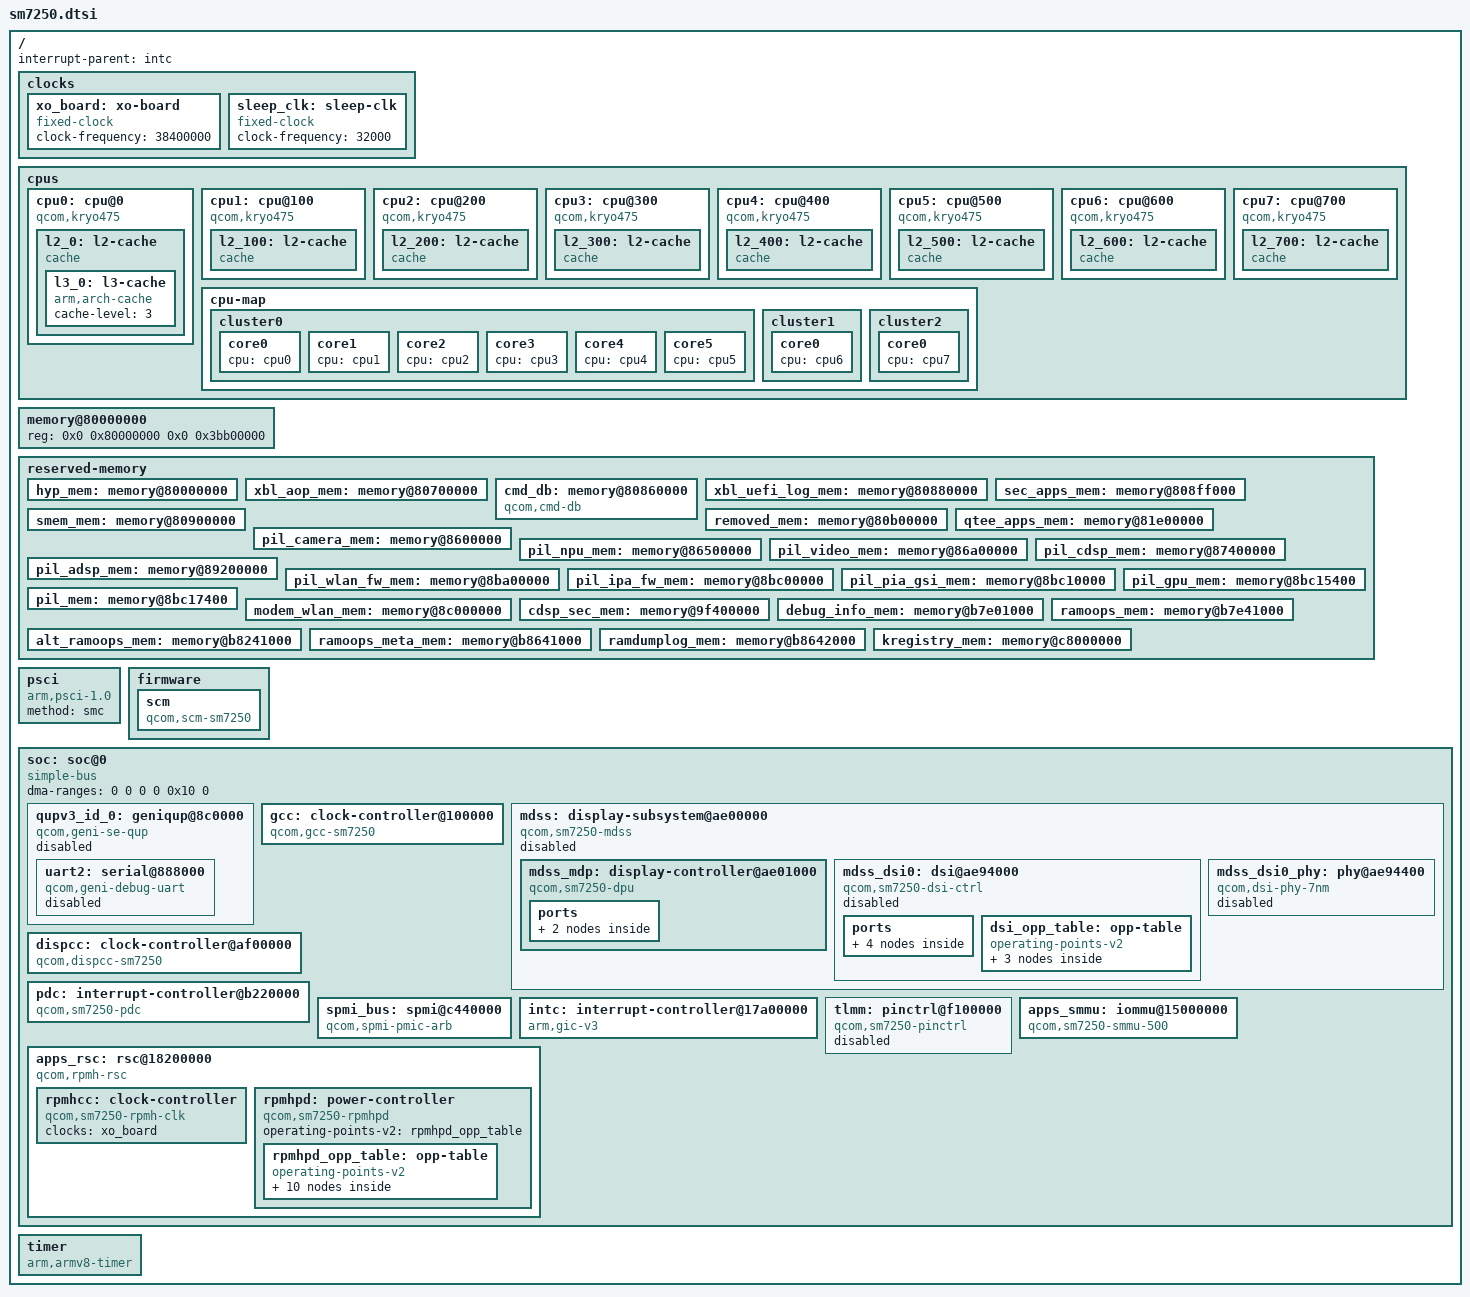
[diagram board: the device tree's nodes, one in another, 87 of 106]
// SPDX-License-Identifier: GPL-2.0
/*
 * Copyright (c) 2025 Mike Jones <mike@mjones.org>
 */

#include <dt-bindings/clock/qcom,dispcc-sm7250.h>
#include <dt-bindings/clock/qcom,dsi-phy-28nm.h>
#include <dt-bindings/clock/qcom,gcc-sm7250.h>
#include <dt-bindings/clock/qcom,rpmh.h>
#include <dt-bindings/interrupt-controller/arm-gic.h>
#include <dt-bindings/power/qcom,rpmhpd.h>
#include <dt-bindings/soc/qcom,rpmh-rsc.h>

/ {
	interrupt-parent = <&intc>;

	#address-cells = <2>;
	#size-cells = <2>;

	clocks {
		xo_board: xo-board {
			compatible = "fixed-clock";
			#clock-cells = <0>;
			clock-frequency = <38400000>;
		};

		sleep_clk: sleep-clk {
			compatible = "fixed-clock";
			#clock-cells = <0>;
			clock-frequency = <32000>;
		};
	};

	cpus {
		#address-cells = <0x02>;
		#size-cells = <0x00>;

		cpu0: cpu@0 {
			device_type = "cpu";
			compatible = "qcom,kryo475";
			reg = <0x0 0x0>;
			enable-method = "psci";
			capacity-dmips-mhz = <1024>;
			dynamic-power-coefficient = <100>;
			next-level-cache = <&l2_0>;
			#cooling-cells = <02>;

			l2_0: l2-cache {
				compatible = "cache";
				cache-level = <2>;
				next-level-cache = <&l3_0>;

				l3_0: l3-cache {
					compatible = "arm,arch-cache";
					cache-level = <3>;
				};
			};
		};
		cpu1: cpu@100 {
			device_type = "cpu";
			compatible = "qcom,kryo475";
			reg = <0x0 0x100>;
			enable-method = "psci";
			capacity-dmips-mhz = <1024>;
			dynamic-power-coefficient = <100>;
			next-level-cache = <&l2_100>;
			#cooling-cells = <02>;

			l2_100: l2-cache {
				compatible = "cache";
				cache-level = <2>;
				next-level-cache = <&l3_0>;
			};
		};

		cpu2: cpu@200 {
			device_type = "cpu";
			compatible = "qcom,kryo475";
			reg = <0x0 0x200>;
			enable-method = "psci";
			capacity-dmips-mhz = <1024>;
			dynamic-power-coefficient = <100>;
			next-level-cache = <&l2_200>;
			#cooling-cells = <02>;

			l2_200: l2-cache {
				compatible = "cache";
				cache-level = <2>;
				next-level-cache = <&l3_0>;
			};
		};
		cpu3: cpu@300 {
			device_type = "cpu";
			compatible = "qcom,kryo475";
			reg = <0x0 0x300>;
			enable-method = "psci";
			capacity-dmips-mhz = <1024>;
			dynamic-power-coefficient = <100>;
			next-level-cache = <&l2_300>;
			#cooling-cells = <02>;

			l2_300: l2-cache {
				compatible = "cache";
				cache-level = <2>;
				next-level-cache = <&l3_0>;
			};
		};

		cpu4: cpu@400 {
			device_type = "cpu";
			compatible = "qcom,kryo475";
			reg = <0x0 0x400>;
			enable-method = "psci";
			capacity-dmips-mhz = <1024>;
			dynamic-power-coefficient = <100>;
			next-level-cache = <&l2_400>;
			#cooling-cells = <02>;

			l2_400: l2-cache {
				compatible = "cache";
				cache-level = <2>;
				next-level-cache = <&l3_0>;
			};
		};

		cpu5: cpu@500 {
			device_type = "cpu";
			compatible = "qcom,kryo475";
			reg = <0x0 0x500>;
			enable-method = "psci";
			capacity-dmips-mhz = <1024>;
			dynamic-power-coefficient = <100>;
			next-level-cache = <&l2_500>;
			#cooling-cells = <02>;

			l2_500: l2-cache {
				compatible = "cache";
				cache-level = <2>;
				next-level-cache = <&l3_0>;
			};
		};

		cpu6: cpu@600 {
			device_type = "cpu";
			compatible = "qcom,kryo475";
			reg = <0x0 0x600>;
			enable-method = "psci";
			capacity-dmips-mhz = <1740>;
			dynamic-power-coefficient = <341>;
			next-level-cache = <&l2_600>;
			#cooling-cells = <2>;

			l2_600: l2-cache {
				compatible = "cache";
				cache-level = <2>;
				next-level-cache = <&l3_0>;
			};
		};

		cpu7: cpu@700 {
			device_type = "cpu";
			compatible = "qcom,kryo475";
			reg = <0x0 0x700>;
			enable-method = "psci";
			capacity-dmips-mhz = <1740>;
			dynamic-power-coefficient = <375>;
			next-level-cache = <&l2_700>;
			#cooling-cells = <2>;

			l2_700: l2-cache {
				compatible = "cache";
				cache-level = <2>;
				next-level-cache = <&l3_0>;
			};
		};

		cpu-map {

			cluster0 {

				core0 {
					cpu = <&cpu0>;
				};

				core1 {
					cpu = <&cpu1>;
				};

				core2 {
					cpu = <&cpu2>;
				};

				core3 {
					cpu = <&cpu3>;
				};

				core4 {
					cpu = <&cpu4>;
				};

				core5 {
					cpu = <&cpu5>;
				};
			};

			cluster1 {

				core0 {
					cpu = <&cpu6>;
				};
			};

			cluster2 {

				core0 {
					cpu = <&cpu7>;
				};
			};
		};
	};

	memory@80000000 {
		device_type = "memory";
		reg = <0x0 0x80000000 0x0 0x3bb00000>;
	};

	reserved-memory {
		#address-cells = <2>;
		#size-cells = <2>;
		ranges;

		hyp_mem: memory@80000000 {
			reg = <0x0 0x80000000 0x0 0x600000>;
			no-map;
		};

		xbl_aop_mem: memory@80700000 {
			reg = <0x0 0x80700000 0x0 0x160000>;
			no-map;
		};

		cmd_db: memory@80860000 {
			compatible = "qcom,cmd-db";
			reg = <0x0 0x80860000 0x0 0x20000>;
			no-map;
		};

		xbl_uefi_log_mem: memory@80880000 {
			reg = <0x0 0x80880000 0x0 0x14000>;
			no-map;
		};

		sec_apps_mem: memory@808ff000 {
			reg = <0x0 0x808ff000 0x0 0x1000>;
			no-map;
		};

		smem_mem: memory@80900000 {
			reg = <0x0 0x80900000 0x0 0x200000>;
			no-map;
		};

		removed_mem: memory@80b00000 {
			reg = <0x0 0x80b00000 0x0 0x1300000>;
			no-map;
		};

		qtee_apps_mem: memory@81e00000 {
			reg = <0x0 0x81e00000 0x0 0x2600000>;
			no-map;
		};

		pil_camera_mem: memory@8600000 {
			reg = <0x0 0x86000000 0x0 0x500000>;
			no-map;
		};

		pil_npu_mem: memory@86500000 {
			reg = <0x0 0x86500000 0x0 0x500000>;
			no-map;
		};

		pil_video_mem: memory@86a00000 {
			reg = <0x0 0x86a00000 0x0 0x500000>;
			no-map;
		};

		pil_cdsp_mem: memory@87400000 {
			reg = <0x0 0x87400000 0x0 0x1e00000>;
			no-map;
		};

		pil_adsp_mem: memory@89200000 {
			reg = <0x0 0x89200000 0x0 0x2800000>;
			no-map;
		};

		pil_wlan_fw_mem: memory@8ba00000 {
			reg = <0x0 0x8ba00000 0x0 0x200000>;
			no-map;
		};

		pil_ipa_fw_mem: memory@8bc00000 {
			reg = <0x0 0x8bc00000 0x0 0x10000>;
			no-map;
		};

		pil_pia_gsi_mem: memory@8bc10000 {
			reg = <0x0 0x8bc10000 0x0 0x5400>;
			no-map;
		};

		pil_gpu_mem: memory@8bc15400 {
			reg = <0x0 0x8bc15400 0x0 0x2000>;
			no-map;
		};

		pil_mem: memory@8bc17400 {
			reg = <0x0 0x8bc17400 0x0 0x3e8c00>;
			no-map;
		};

		modem_wlan_mem: memory@8c000000 {
			reg = <0x0 0x8c000000 0x0 0x11800000>;
			no-map;
		};

		cdsp_sec_mem: memory@9f400000 {
			reg = <0x0 0x9f400000 0x0 0xc00000>;
			no-map;
		};

		debug_info_mem: memory@b7e01000 {
			reg = <0x0 0xb7e01000 0x0 0x40000>;
			no-map;
		};

		ramoops_mem: memory@b7e41000 {
			reg = <0x0 0xb7e41000 0x0 0x400000>;
			no-map;
		};

		alt_ramoops_mem: memory@b8241000 {
			reg = <0x00 0xb8241000 0x00 0x400000>;
			no-map;
		};

		ramoops_meta_mem: memory@b8641000 {
			reg = <0x0 0xb8641000 0x0 0x1000>;
			no-map;
		};

		ramdumplog_mem: memory@b8642000 {
			reg = <0x0 0xb8642000 0x0 0x10000>;
			no-map;
		};

		kregistry_mem: memory@c8000000 {
			reg = <0x0 0xc8000000 0x0 0x10000>;
			no-map;
		};
	};

	psci {
		compatible = "arm,psci-1.0";
		method = "smc";
	};

	firmware {
		scm: scm {
			compatible = "qcom,scm-sm7250", "qcom,scm";
		};
	};

	soc: soc@0 {
		#address-cells = <2>;
		#size-cells = <2>;
		ranges = <0 0 0 0 0x10 0>;
		dma-ranges = <0 0 0 0 0x10 0>;
		compatible = "simple-bus";

		qupv3_id_0: geniqup@8c0000 {
			compatible = "qcom,geni-se-qup";
			reg = <0x0 0x8c0000 0x0 0x2000>;
			clock-names = "m-ahb", "s-ahb";
			clocks = <&gcc GCC_QUPV3_WRAP_0_M_AHB_CLK>,
				 <&gcc GCC_QUPV3_WRAP_0_S_AHB_CLK>;
			#address-cells = <2>;
			#size-cells = <2>;
			ranges;
			status = "disabled";

			uart2: serial@888000 {
				compatible = "qcom,geni-debug-uart";
				reg = <0x0 0x888000 0x0 0x4000>;
				clock-names = "se";
				clocks = <&gcc GCC_QUPV3_WRAP0_S2_CLK>;
				interrupts = <GIC_SPI 603 IRQ_TYPE_LEVEL_HIGH>;
				status = "disabled";
			};
		};

		gcc: clock-controller@100000 {
			compatible = "qcom,gcc-sm7250";
			reg = <0x0 0x100000 0x0 0x1f0000>;
			#clock-cells = <1>;
			#reset-cells = <1>;
			#power-domain-cells = <1>;
			clock-names = "bi_tcxo",
				      "bi_tcxo_ao",
				      "sleep_clk";
			clocks = <&xo_board>,
				 <&xo_board>,
				 <&sleep_clk>;
		};

		mdss: display-subsystem@ae00000 {
			compatible = "qcom,sm7250-mdss";
			reg = <0 0x0ae00000 0 0x1000>;
			reg-names = "mdss";

			power-domains = <&dispcc MDSS_GDSC>;

			clocks = <&dispcc DISP_CC_MDSS_AHB_CLK>,
				 <&gcc GCC_DISP_HF_AXI_CLK>,
				 <&gcc GCC_DISP_SF_AXI_CLK>,
				 <&dispcc DISP_CC_MDSS_MDP_CLK>;
			clock-names = "iface", "bus", "nrt_bus", "core";

			interrupts = <GIC_SPI 83 IRQ_TYPE_LEVEL_HIGH>;
			interrupt-controller;
			#interrupt-cells = <1>;

			iommus = <&apps_smmu 0xb40 0x402>;

			status = "disabled";

			#address-cells = <2>;
			#size-cells = <2>;
			ranges;

			mdss_mdp: display-controller@ae01000 {
				compatible = "qcom,sm7250-dpu";
				reg = <0 0x0ae01000 0 0x8f000>,
				      <0 0x0aeb0000 0 0x3000>;
				reg-names = "mdp", "vbif";

				clocks = <&dispcc DISP_CC_MDSS_AHB_CLK>,
					 <&gcc GCC_DISP_HF_AXI_CLK>,
					 <&dispcc DISP_CC_MDSS_MDP_CLK>,
					 <&dispcc DISP_CC_MDSS_VSYNC_CLK>;
				clock-names = "iface", "bus", "core", "vsync";

				assigned-clocks = <&dispcc DISP_CC_MDSS_VSYNC_CLK>;
				assigned-clock-rates = <19200000>;

				power-domains = <&rpmhpd RPMHPD_CX>;

				interrupt-parent = <&mdss>;
				interrupts = <0>;

				ports {
					#address-cells = <1>;
					#size-cells = <0>;

					port@0 {
						reg = <0>;
						dpu_intf1_out: endpoint {
							remote-endpoint = <&mdss_dsi0_in>;
						};
					};
				};
			};

			mdss_dsi0: dsi@ae94000 {
				compatible = "qcom,sm7250-dsi-ctrl",
					     "qcom,mdss-dsi-ctrl";
				reg = <0 0x0ae94000 0 0x400>;
				reg-names = "dsi_ctrl";

				interrupt-parent = <&mdss>;
				interrupts = <4>;

				clocks = <&dispcc DISP_CC_MDSS_BYTE0_CLK>,
					 <&dispcc DISP_CC_MDSS_BYTE0_INTF_CLK>,
					 <&dispcc DISP_CC_MDSS_PCLK0_CLK>,
					 <&dispcc DISP_CC_MDSS_ESC0_CLK>,
					 <&dispcc DISP_CC_MDSS_AHB_CLK>,
					 <&gcc GCC_DISP_HF_AXI_CLK>;
				clock-names = "byte",
					      "byte_intf",
					      "pixel",
					      "core",
					      "iface",
					      "bus";

				assigned-clocks = <&dispcc DISP_CC_MDSS_BYTE0_CLK_SRC>,
						  <&dispcc DISP_CC_MDSS_PCLK0_CLK_SRC>;
				assigned-clock-parents = <&mdss_dsi0_phy DSI_BYTE_PLL_CLK>,
							 <&mdss_dsi0_phy DSI_PIXEL_PLL_CLK>;

				operating-points-v2 = <&dsi_opp_table>;
				power-domains = <&rpmhpd RPMHPD_CX>;

				phys = <&mdss_dsi0_phy>;
				phy-names = "dsi";

				#address-cells = <1>;
				#size-cells = <0>;

				status = "disabled";

				ports {
					#address-cells = <1>;
					#size-cells = <0>;

					port@0 {
						reg = <0>;
						mdss_dsi0_in: endpoint {
							remote-endpoint = <&dpu_intf1_out>;
						};
					};

					port@1 {
						reg = <1>;
						mdss_dsi0_out: endpoint {
						};
					};
				};

				dsi_opp_table: opp-table {
					compatible = "operating-points-v2";

					opp-187500000 {
						opp-hz = /bits/ 64 <187500000>;
						required-opps = <&rpmhpd_opp_low_svs>;
					};

					opp-300000000 {
						opp-hz = /bits/ 64 <300000000>;
						required-opps = <&rpmhpd_opp_svs>;
					};

					opp-358000000 {
						opp-hz = /bits/ 64 <358000000>;
						required-opps = <&rpmhpd_opp_svs_l1>;
					};
				};
			};

			mdss_dsi0_phy: phy@ae94400 {
				compatible = "qcom,dsi-phy-7nm";
				reg = <0 0x0ae94400 0 0x200>,
				      <0 0x0ae94600 0 0x280>,
				      <0 0x0ae94900 0 0x260>;
				reg-names = "dsi_phy",
					    "dsi_phy_lane",
					    "dsi_pll";

				#clock-cells = <1>;
				#phy-cells = <0>;

				clocks = <&dispcc DISP_CC_MDSS_AHB_CLK>,
					 <&rpmhcc RPMH_CXO_CLK>;
				clock-names = "iface", "ref";

				status = "disabled";
			};
		};

		dispcc: clock-controller@af00000 {
			compatible = "qcom,dispcc-sm7250";
			reg = <0x0 0xaf00000 0x0 0x20000>;
			power-domains = <&rpmhpd RPMHPD_CX>;
			clocks = <&rpmhcc RPMH_CXO_CLK>,
				 <&rpmhcc RPMH_CXO_CLK_A>,
				 <&gcc GCC_DISP_GPLL0_CLK_SRC>,
				 <&mdss_dsi0_phy DSI_BYTE_PLL_CLK>,
				 <&mdss_dsi0_phy DSI_PIXEL_PLL_CLK>,
				 <&sleep_clk>;
			clock-names = "bi_tcxo",
				      "bi_tcxo_ao",
				      "gcc_disp_gpll0_clk_src",
				      "dsi0_phy_pll_out_byteclk",
				      "dsi0_phy_pll_out_dsiclk",
				      "sleep_clk";
			#clock-cells = <1>;
			#reset-cells = <1>;
			#power-domain-cells = <1>;
		};

		pdc: interrupt-controller@b220000 {
			compatible = "qcom,sm7250-pdc", "qcom,pdc";
			reg = <0 0xb220000 0 0x30000>, <0 0x17c000f0 0 0x60>;
			qcom,pdc-ranges = <0 480 42>, <42 612 28>, <70 63 1>,
					  <71 640 15>, <86 522 52>;
			#interrupt-cells = <2>;
			interrupt-parent = <&intc>;
			interrupt-controller;
		};

		spmi_bus: spmi@c440000 {
			compatible = "qcom,spmi-pmic-arb";
			reg = <0x0 0xc440000 0x0 0x0001100>,
			      <0x0 0xc600000 0x0 0x2000000>,
			      <0x0 0xe600000 0x0 0x0100000>,
			      <0x0 0xe700000 0x0 0x00a0000>,
			      <0x0 0xc40a000 0x0 0x0026000>;
			reg-names = "core", "chnls", "obsrvr", "intr", "cnfg";
			interrupt-names = "periph_irq";
			interrupts-extended = <&pdc 1 IRQ_TYPE_LEVEL_HIGH>;
			qcom,ee = <0>;
			qcom,channel = <0>;
			#address-cells = <2>;
			#size-cells = <0>;
			interrupt-controller;
			#interrupt-cells = <4>;
		};

		intc: interrupt-controller@17a00000 {
			compatible = "arm,gic-v3";
			#address-cells = <0>;
			#interrupt-cells = <3>;
			interrupt-controller;
			reg = <0x0 0x17a00000 0x0 0x10000>,     /* GICD */
			      <0x0 0x17a60000 0x0 0x100000>;    /* GICR * 8 */
			interrupts = <GIC_PPI 8 IRQ_TYPE_LEVEL_HIGH>;
		};

		tlmm: pinctrl@f100000 {
			compatible = "qcom,sm7250-pinctrl";
			reg = <0 0x0f100000 0 0x300000>,
			      <0 0x0f500000 0 0x300000>,
			      <0 0x0f900000 0 0x300000>;
			reg-names = "south", "west", "east";
			interrupts = <GIC_SPI 208 IRQ_TYPE_LEVEL_HIGH>;
			gpio-controller;
			#gpio-cells = <2>;
			interrupt-controller;
			#interrupt-cells = <2>;
			gpio-ranges = <&tlmm 0 0 181>;
			gpio-reserved-ranges = <0 4>;
			wakeup-parent = <&pdc>;
			status = "disabled";
		};

		apps_smmu: iommu@15000000 {
			compatible = "qcom,sm7250-smmu-500", "qcom,smmu-500", "arm,mmu-500";
			reg = <0 0x15000000 0 0x100000>;
			#iommu-cells = <2>;
			#global-interrupts = <1>;
			dma-coherent;
			interrupts = <GIC_SPI 65 IRQ_TYPE_LEVEL_HIGH>,
				     <GIC_SPI 97 IRQ_TYPE_LEVEL_HIGH>,
				     <GIC_SPI 98 IRQ_TYPE_LEVEL_HIGH>,
				     <GIC_SPI 99 IRQ_TYPE_LEVEL_HIGH>,
				     <GIC_SPI 100 IRQ_TYPE_LEVEL_HIGH>,
				     <GIC_SPI 101 IRQ_TYPE_LEVEL_HIGH>,
				     <GIC_SPI 102 IRQ_TYPE_LEVEL_HIGH>,
				     <GIC_SPI 103 IRQ_TYPE_LEVEL_HIGH>,
				     <GIC_SPI 104 IRQ_TYPE_LEVEL_HIGH>,
				     <GIC_SPI 105 IRQ_TYPE_LEVEL_HIGH>,
				     <GIC_SPI 106 IRQ_TYPE_LEVEL_HIGH>,
				     <GIC_SPI 107 IRQ_TYPE_LEVEL_HIGH>,
				     <GIC_SPI 108 IRQ_TYPE_LEVEL_HIGH>,
				     <GIC_SPI 109 IRQ_TYPE_LEVEL_HIGH>,
				     <GIC_SPI 110 IRQ_TYPE_LEVEL_HIGH>,
				     <GIC_SPI 111 IRQ_TYPE_LEVEL_HIGH>,
				     <GIC_SPI 112 IRQ_TYPE_LEVEL_HIGH>,
				     <GIC_SPI 113 IRQ_TYPE_LEVEL_HIGH>,
				     <GIC_SPI 114 IRQ_TYPE_LEVEL_HIGH>,
				     <GIC_SPI 115 IRQ_TYPE_LEVEL_HIGH>,
				     <GIC_SPI 116 IRQ_TYPE_LEVEL_HIGH>,
				     <GIC_SPI 117 IRQ_TYPE_LEVEL_HIGH>,
				     <GIC_SPI 118 IRQ_TYPE_LEVEL_HIGH>,
				     <GIC_SPI 181 IRQ_TYPE_LEVEL_HIGH>,
				     <GIC_SPI 182 IRQ_TYPE_LEVEL_HIGH>,
				     <GIC_SPI 183 IRQ_TYPE_LEVEL_HIGH>,
				     <GIC_SPI 184 IRQ_TYPE_LEVEL_HIGH>,
				     <GIC_SPI 179 IRQ_TYPE_LEVEL_HIGH>,
				     <GIC_SPI 186 IRQ_TYPE_LEVEL_HIGH>,
				     <GIC_SPI 187 IRQ_TYPE_LEVEL_HIGH>,
				     <GIC_SPI 188 IRQ_TYPE_LEVEL_HIGH>,
				     <GIC_SPI 189 IRQ_TYPE_LEVEL_HIGH>,
				     <GIC_SPI 190 IRQ_TYPE_LEVEL_HIGH>,
				     <GIC_SPI 191 IRQ_TYPE_LEVEL_HIGH>,
				     <GIC_SPI 192 IRQ_TYPE_LEVEL_HIGH>,
				     <GIC_SPI 315 IRQ_TYPE_LEVEL_HIGH>,
				     <GIC_SPI 316 IRQ_TYPE_LEVEL_HIGH>,
				     <GIC_SPI 317 IRQ_TYPE_LEVEL_HIGH>,
				     <GIC_SPI 318 IRQ_TYPE_LEVEL_HIGH>,
				     <GIC_SPI 319 IRQ_TYPE_LEVEL_HIGH>,
				     <GIC_SPI 320 IRQ_TYPE_LEVEL_HIGH>,
				     <GIC_SPI 321 IRQ_TYPE_LEVEL_HIGH>,
				     <GIC_SPI 322 IRQ_TYPE_LEVEL_HIGH>,
				     <GIC_SPI 323 IRQ_TYPE_LEVEL_HIGH>,
				     <GIC_SPI 324 IRQ_TYPE_LEVEL_HIGH>,
				     <GIC_SPI 325 IRQ_TYPE_LEVEL_HIGH>,
				     <GIC_SPI 326 IRQ_TYPE_LEVEL_HIGH>,
				     <GIC_SPI 327 IRQ_TYPE_LEVEL_HIGH>,
				     <GIC_SPI 328 IRQ_TYPE_LEVEL_HIGH>,
				     <GIC_SPI 329 IRQ_TYPE_LEVEL_HIGH>,
				     <GIC_SPI 330 IRQ_TYPE_LEVEL_HIGH>,
				     <GIC_SPI 331 IRQ_TYPE_LEVEL_HIGH>,
				     <GIC_SPI 332 IRQ_TYPE_LEVEL_HIGH>,
				     <GIC_SPI 333 IRQ_TYPE_LEVEL_HIGH>,
				     <GIC_SPI 334 IRQ_TYPE_LEVEL_HIGH>,
				     <GIC_SPI 335 IRQ_TYPE_LEVEL_HIGH>,
				     <GIC_SPI 336 IRQ_TYPE_LEVEL_HIGH>,
				     <GIC_SPI 337 IRQ_TYPE_LEVEL_HIGH>,
				     <GIC_SPI 338 IRQ_TYPE_LEVEL_HIGH>,
				     <GIC_SPI 339 IRQ_TYPE_LEVEL_HIGH>,
				     <GIC_SPI 340 IRQ_TYPE_LEVEL_HIGH>,
				     <GIC_SPI 341 IRQ_TYPE_LEVEL_HIGH>,
				     <GIC_SPI 342 IRQ_TYPE_LEVEL_HIGH>,
				     <GIC_SPI 343 IRQ_TYPE_LEVEL_HIGH>,
				     <GIC_SPI 344 IRQ_TYPE_LEVEL_HIGH>,
				     <GIC_SPI 345 IRQ_TYPE_LEVEL_HIGH>,
				     <GIC_SPI 395 IRQ_TYPE_LEVEL_HIGH>,
				     <GIC_SPI 396 IRQ_TYPE_LEVEL_HIGH>,
				     <GIC_SPI 397 IRQ_TYPE_LEVEL_HIGH>,
				     <GIC_SPI 398 IRQ_TYPE_LEVEL_HIGH>,
				     <GIC_SPI 399 IRQ_TYPE_LEVEL_HIGH>,
				     <GIC_SPI 400 IRQ_TYPE_LEVEL_HIGH>,
				     <GIC_SPI 401 IRQ_TYPE_LEVEL_HIGH>,
				     <GIC_SPI 402 IRQ_TYPE_LEVEL_HIGH>,
				     <GIC_SPI 403 IRQ_TYPE_LEVEL_HIGH>,
				     <GIC_SPI 404 IRQ_TYPE_LEVEL_HIGH>,
				     <GIC_SPI 405 IRQ_TYPE_LEVEL_HIGH>,
				     <GIC_SPI 406 IRQ_TYPE_LEVEL_HIGH>,
				     <GIC_SPI 407 IRQ_TYPE_LEVEL_HIGH>,
				     <GIC_SPI 408 IRQ_TYPE_LEVEL_HIGH>,
				     <GIC_SPI 409 IRQ_TYPE_LEVEL_HIGH>;
		};

		apps_rsc: rsc@18200000 {
			label = "apps_rsc";
			compatible = "qcom,rpmh-rsc";
			reg = <0x0 0x18200000 0x0 0x10000>,
			      <0x0 0x18210000 0x0 0x10000>,
			      <0x0 0x18220000 0x0 0x10000>;
			reg-names = "drv-0", "drv-1", "drv-2";
			interrupts = <GIC_SPI 3 IRQ_TYPE_LEVEL_HIGH>,
				     <GIC_SPI 4 IRQ_TYPE_LEVEL_HIGH>,
				     <GIC_SPI 5 IRQ_TYPE_LEVEL_HIGH>;
			qcom,tcs-offset = <0xd00>;
			qcom,drv-id = <2>;
			qcom,tcs-config = <ACTIVE_TCS  2>, <SLEEP_TCS   3>,
					  <WAKE_TCS    3>, <CONTROL_TCS 1>;

			rpmhcc: clock-controller {
				compatible = "qcom,sm7250-rpmh-clk";
				#clock-cells = <1>;
				clock-names = "xo";
				clocks = <&xo_board>;
			};

			rpmhpd: power-controller {
				compatible = "qcom,sm7250-rpmhpd";
				#power-domain-cells = <1>;
				operating-points-v2 = <&rpmhpd_opp_table>;

				rpmhpd_opp_table: opp-table {
					compatible = "operating-points-v2";

					rpmhpd_opp_ret: opp1 {
						opp-level = <RPMH_REGULATOR_LEVEL_RETENTION>;
					};

					rpmhpd_opp_min_svs: opp2 {
						opp-level = <RPMH_REGULATOR_LEVEL_MIN_SVS>;
					};

					rpmhpd_opp_low_svs: opp3 {
						opp-level = <RPMH_REGULATOR_LEVEL_LOW_SVS>;
					};

					rpmhpd_opp_svs: opp4 {
						opp-level = <RPMH_REGULATOR_LEVEL_SVS>;
					};

					rpmhpd_opp_svs_l1: opp5 {
						opp-level = <RPMH_REGULATOR_LEVEL_SVS_L1>;
					};

					rpmhpd_opp_nom: opp6 {
						opp-level = <RPMH_REGULATOR_LEVEL_NOM>;
					};

					rpmhpd_opp_nom_l1: opp7 {
						opp-level = <RPMH_REGULATOR_LEVEL_NOM_L1>;
					};

					rpmhpd_opp_nom_l2: opp8 {
						opp-level = <RPMH_REGULATOR_LEVEL_NOM_L2>;
					};

					rpmhpd_opp_turbo: opp9 {
						opp-level = <RPMH_REGULATOR_LEVEL_TURBO>;
					};

					rpmhpd_opp_turbo_l1: opp10 {
						opp-level = <RPMH_REGULATOR_LEVEL_TURBO_L1>;
					};
				};
			};
		};
	};

	timer {
		compatible = "arm,armv8-timer";
		interrupts = <GIC_PPI 1 (GIC_CPU_MASK_SIMPLE(8) | IRQ_TYPE_LEVEL_LOW)>,
			     <GIC_PPI 2 (GIC_CPU_MASK_SIMPLE(8) | IRQ_TYPE_LEVEL_LOW)>,
			     <GIC_PPI 3 (GIC_CPU_MASK_SIMPLE(8) | IRQ_TYPE_LEVEL_LOW)>,
			     <GIC_PPI 0 (GIC_CPU_MASK_SIMPLE(8) | IRQ_TYPE_LEVEL_LOW)>;
	};
};
